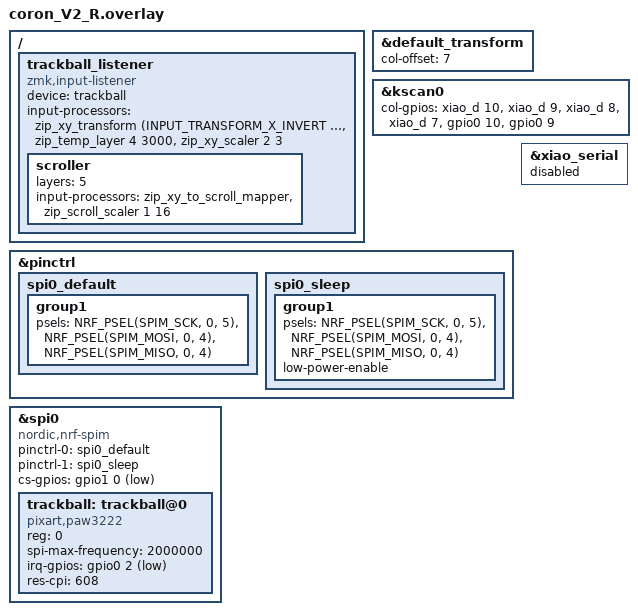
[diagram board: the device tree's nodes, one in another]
#include "coron_V2.dtsi"

#include <input/processors.dtsi>
#include <dt-bindings/zmk/input_transform.h>

&default_transform {
    col-offset = <7>;
};

&kscan0 {
    col-gpios
        = <&xiao_d 10 GPIO_ACTIVE_HIGH>   /* Col 0: P1.15 */
        , <&xiao_d 9 GPIO_ACTIVE_HIGH>    /* Col 1: P1.14 */
        , <&xiao_d 8 GPIO_ACTIVE_HIGH>    /* Col 2: P1.13 */
        , <&xiao_d 7 GPIO_ACTIVE_HIGH>    /* Col 3: P1.12 */
        , <&gpio0 10 GPIO_ACTIVE_HIGH>    /* Col 4: P0.10 (NFC2 pad) */
        , <&gpio0 9 GPIO_ACTIVE_HIGH>     /* Col 5: P0.09 (NFC1 pad) - freed by tying PAW3222 CS to GND */
        ;
};

/ {
    trackball_listener {
        status = "okay";
        compatible = "zmk,input-listener";
        device = <&trackball>;

        /* X/Y are both inverted relative to the sensor's mounting orientation.
           Auto-mouse layer: PAW3222 driver has no built-in automouse,
           so it is done with an input processor (layer 4, 3000 ms).
           The language-switch combos (&to_layer_0) leave it early. */
        input-processors =
            <&zip_xy_transform (INPUT_TRANSFORM_X_INVERT | INPUT_TRANSFORM_Y_INVERT)>,
            <&zip_temp_layer 4 3000>,
            /* res-cpi is already at the PAW3222 minimum (608), so the rest of
               the sensitivity tuning is done here. 2/3 of raw speed. */
            <&zip_xy_scaler 2 3>;

        scroller {
            layers = <5>;
            input-processors =
                <&zip_xy_to_scroll_mapper>,
                <&zip_scroll_scaler 1 16>;
        };
    };
};

&pinctrl {
    /* PAW3222 in 2-wire mode: SCLK + bidirectional SDIO.
       MOSI and MISO are both mapped to P0.04 (SDIO). */
    spi0_default: spi0_default {
        group1 {
            psels = <NRF_PSEL(SPIM_SCK, 0, 5)>,
                <NRF_PSEL(SPIM_MOSI, 0, 4)>,
                <NRF_PSEL(SPIM_MISO, 0, 4)>;
        };
    };

    spi0_sleep: spi0_sleep {
        group1 {
            psels = <NRF_PSEL(SPIM_SCK, 0, 5)>,
                <NRF_PSEL(SPIM_MOSI, 0, 4)>,
                <NRF_PSEL(SPIM_MISO, 0, 4)>;
            low-power-enable;
        };
    };
};

&xiao_serial { status = "disabled"; };

&spi0 {
    status = "okay";
    compatible = "nordic,nrf-spim";
    pinctrl-0 = <&spi0_default>;
    pinctrl-1 = <&spi0_sleep>;
    pinctrl-names = "default", "sleep";

    /* CS is hard-wired to GND on the PCB. Zephyr's SPI API still wants a CS
       line, so point it at P1.00, which is left unconnected on this board. */
    cs-gpios = <&gpio1 0 GPIO_ACTIVE_LOW>;

    trackball: trackball@0 {
        status = "okay";
        compatible = "pixart,paw3222";
        reg = <0>;
        spi-max-frequency = <2000000>;
        irq-gpios = <&gpio0 2 (GPIO_ACTIVE_LOW | GPIO_PULL_UP)>;  /* MOTION: P0.02 */
        res-cpi = <608>;   /* multiple of 38, 608..4826 */
    };
};
